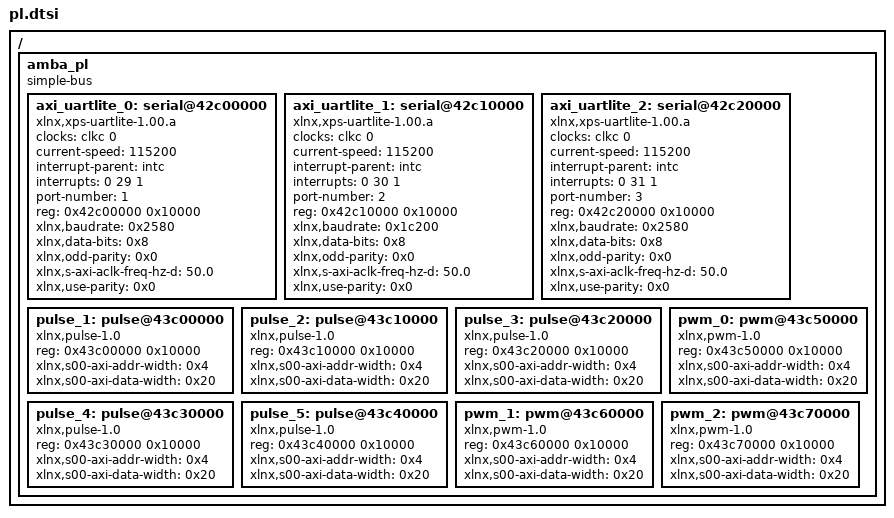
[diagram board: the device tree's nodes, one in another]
/*
 * CAUTION: This file is automatically generated by Xilinx.
 * Version:  
 * Today is: Thu Mar 10 14:25:57 2016
*/


/ {
	amba_pl: amba_pl {
		#address-cells = <1>;
		#size-cells = <1>;
		compatible = "simple-bus";
		ranges ;
		axi_uartlite_0: serial@42c00000 {
			clock-names = "ref_clk";
			clocks = "clkc 0";
			compatible = "xlnx,xps-uartlite-1.00.a";
			current-speed = <115200>;
			device_type = "serial";
			interrupt-parent = <&intc>;
			interrupts = <0 29 1>;
			port-number = <1>;
			reg = <0x42c00000 0x10000>;
			xlnx,baudrate = <0x2580>;
			xlnx,data-bits = <0x8>;
			xlnx,odd-parity = <0x0>;
			xlnx,s-axi-aclk-freq-hz-d = "50.0";
			xlnx,use-parity = <0x0>;
		};
		axi_uartlite_1: serial@42c10000 {
			clock-names = "ref_clk";
			clocks = "clkc 0";
			compatible = "xlnx,xps-uartlite-1.00.a";
			current-speed = <115200>;
			device_type = "serial";
			interrupt-parent = <&intc>;
			interrupts = <0 30 1>;
			port-number = <2>;
			reg = <0x42c10000 0x10000>;
			xlnx,baudrate = <0x1c200>;
			xlnx,data-bits = <0x8>;
			xlnx,odd-parity = <0x0>;
			xlnx,s-axi-aclk-freq-hz-d = "50.0";
			xlnx,use-parity = <0x0>;
		};
		axi_uartlite_2: serial@42c20000 {
			clock-names = "ref_clk";
			clocks = "clkc 0";
			compatible = "xlnx,xps-uartlite-1.00.a";
			current-speed = <115200>;
			device_type = "serial";
			interrupt-parent = <&intc>;
			interrupts = <0 31 1>;
			port-number = <3>;
			reg = <0x42c20000 0x10000>;
			xlnx,baudrate = <0x2580>;
			xlnx,data-bits = <0x8>;
			xlnx,odd-parity = <0x0>;
			xlnx,s-axi-aclk-freq-hz-d = "50.0";
			xlnx,use-parity = <0x0>;
		};
		pulse_1: pulse@43c00000 {
			compatible = "xlnx,pulse-1.0";
			reg = <0x43c00000 0x10000>;
			xlnx,s00-axi-addr-width = <0x4>;
			xlnx,s00-axi-data-width = <0x20>;
		};
		pulse_2: pulse@43c10000 {
			compatible = "xlnx,pulse-1.0";
			reg = <0x43c10000 0x10000>;
			xlnx,s00-axi-addr-width = <0x4>;
			xlnx,s00-axi-data-width = <0x20>;
		};
		pulse_3: pulse@43c20000 {
			compatible = "xlnx,pulse-1.0";
			reg = <0x43c20000 0x10000>;
			xlnx,s00-axi-addr-width = <0x4>;
			xlnx,s00-axi-data-width = <0x20>;
		};
		pulse_4: pulse@43c30000 {
			compatible = "xlnx,pulse-1.0";
			reg = <0x43c30000 0x10000>;
			xlnx,s00-axi-addr-width = <0x4>;
			xlnx,s00-axi-data-width = <0x20>;
		};
		pulse_5: pulse@43c40000 {
			compatible = "xlnx,pulse-1.0";
			reg = <0x43c40000 0x10000>;
			xlnx,s00-axi-addr-width = <0x4>;
			xlnx,s00-axi-data-width = <0x20>;
		};
		pwm_0: pwm@43c50000 {
			compatible = "xlnx,pwm-1.0";
			reg = <0x43c50000 0x10000>;
			xlnx,s00-axi-addr-width = <0x4>;
			xlnx,s00-axi-data-width = <0x20>;
		};
		pwm_1: pwm@43c60000 {
			compatible = "xlnx,pwm-1.0";
			reg = <0x43c60000 0x10000>;
			xlnx,s00-axi-addr-width = <0x4>;
			xlnx,s00-axi-data-width = <0x20>;
		};
		pwm_2: pwm@43c70000 {
			compatible = "xlnx,pwm-1.0";
			reg = <0x43c70000 0x10000>;
			xlnx,s00-axi-addr-width = <0x4>;
			xlnx,s00-axi-data-width = <0x20>;
		};
	};
};
